# CM_CORE__COREAON register map
Vendor: Texas Instruments
Peripheral module from a debugger description file (folder DRA74xP_75xP_76xP_77xP).
Registers are 32-bit, access per field, reset 0x0 unless marked. A register's access mark holds for its fields unless they carry their own. Offsets are as the file gives them; lines under a group give offsets from that group; [hi:lo] are bit positions; {n}, {i} and the like mark numbered series; 'fields as' and 'values as' point back to an identical list; <NAME> marks a mode.

## CM_CORE__COREAON
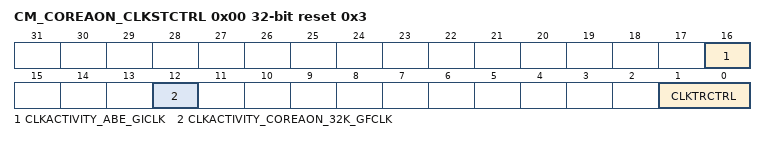
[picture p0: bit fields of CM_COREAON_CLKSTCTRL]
0x00 CM_COREAON_CLKSTCTRL reset 0x3 — This register enables the domain power state transition. It controls the HW supervised domain power state transition between ON-ACTIVE and ON-INACTIVE states. It also hold one status bit per clock input of the domain.
  [16] CLKACTIVITY_ABE_GICLK ro — This field indicates the state of the ABE_GICLK clock input of the domain. [warm reset insensitive]
    0=INACT (Corresponding clock is definitely gated); 1=ACT (Corresponding clock is running or gating/ungating transition is on-going)
  [12] CLKACTIVITY_COREAON_32K_GFCLK ro — This field indicates the state of the COREAON_32K_GFCLK clock in the domain. [warm reset insensitive]
    values as CLKACTIVITY_ABE_GICLK
  [1:0] CLKTRCTRL rw — Controls the clock state transition of the COREAON clock domain.
    0=NO_SLEEP (NO_SLEEP: Sleep transition cannot be initiated. Wakeup transition may however occur.); 2=SW_WKUP (SW_WKUP: Start a software forced wake-up transition on the domain.); 3=HW_AUTO (HW_AUTO: Automatic transition is enabled. Sleep and wakeup transition are based upon hardware conditions.)
0x40 CM_COREAON_USB_PHY1_CORE_CLKCTRL — This register manages the USB PHY 32KHz clock.
  [8] OPTFCLKEN_CLK32K rw — Optional functional clock control.
    0=FCLK_DIS (Optional functional clock is disabled); 1=FCLK_EN (Optional functional clock is enabled)
0x88 CM_COREAON_USB_PHY2_CORE_CLKCTRL — This register manages the USB PHY 32KHz clock.
  fields as CM_COREAON_USB_PHY1_CORE_CLKCTRL
0x98 CM_COREAON_USB_PHY3_CORE_CLKCTRL — This register manages the USB PHY 32KHz clock.
  fields as CM_COREAON_USB_PHY1_CORE_CLKCTRL
0xA0 CM_COREAON_CLKOUTMUX1_CLKCTRL — Used for controlling the CLKOUTMUX 1 gate.
  [8] OPTFCLKEN_CLKOUTMUX1_CLK rw — Optional functional clock control.
    values as CM_COREAON_USB_PHY1_CORE_CLKCTRL.OPTFCLKEN_CLK32K
0xB0 CM_COREAON_CLKOUTMUX2_CLKCTRL — Used for controlling the CLKOUTMUX 2 gate.
  [8] OPTFCLKEN_CLKOUTMUX2_CLK rw — Optional functional clock control.
    values as CM_COREAON_USB_PHY1_CORE_CLKCTRL.OPTFCLKEN_CLK32K
0xC0 CM_COREAON_L3INIT_60M_GFCLK_CLKCTRL — Used for controlling the L3INIT_60M_GFCLK gate.
  [8] OPTFCLKEN_L3INIT_60M_GFCLK rw — Optional functional clock control; used to control the clock of USB2PHY2.
    values as CM_COREAON_USB_PHY1_CORE_CLKCTRL.OPTFCLKEN_CLK32K
0xD0 CM_COREAON_ABE_GICLK_CLKCTRL — Used for controlling ABE_GICLK gate.
  [8] OPTFCLKEN_ABE_GICLK rw — Optional functional clock control.
    values as CM_COREAON_USB_PHY1_CORE_CLKCTRL.OPTFCLKEN_CLK32K
